# STM32F40x register map
File version: 1.5
Registers are 32-bit, read-write, reset 0x0 unless marked. A register's access mark holds for its fields unless they carry their own. Offsets are from the block's base; [hi:lo] are bit positions.

## TIM9（定时器9(通用定时器)） — 通用定时器：计数/比较/PWM/输入捕获 | General purpose timers
Base 0x40014000
Same registers: TIM12（定时器12(通用定时器)） 0x40001800
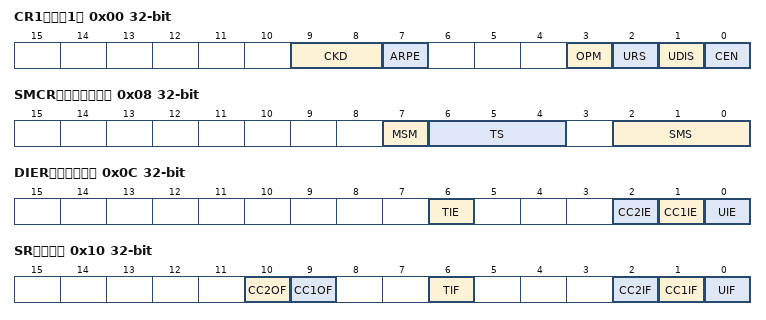
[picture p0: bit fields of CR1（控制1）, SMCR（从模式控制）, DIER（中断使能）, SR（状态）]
0x00 CR1（控制1） — 控制1：计数器使能/方向/分频 | control register 1
  [9:8] CKD — Clock division
  [7] ARPE — Auto-reload preload enable
  [3] OPM — One-pulse mode
  [2] URS — Update request source
  [1] UDIS — Update disable
  [0] CEN — Counter enable
0x04 CR2（控制2） — 控制2：主模式选择 | control register 2
  [6:4] MMS — Master mode selection
0x08 SMCR（从模式控制） — 从模式控制 | slave mode control register
  [7] MSM — Master/Slave mode
  [6:4] TS — Trigger selection
  [2:0] SMS — Slave mode selection
0x0C DIER（中断使能） — DMA/中断使能 | DMA/Interrupt enable register
  [6] TIE — Trigger interrupt enable
  [2] CC2IE — Capture/Compare 2 interrupt enable
  [1] CC1IE — Capture/Compare 1 interrupt enable
  [0] UIE — Update interrupt enable
0x10 SR（状态） — 状态：更新/捕获 标志 | status register
  [10] CC2OF — Capture/compare 2 overcapture flag
  [9] CC1OF — Capture/Compare 1 overcapture flag
  [6] TIF — Trigger interrupt flag
  [2] CC2IF — Capture/Compare 2 interrupt flag
  [1] CC1IF — Capture/compare 1 interrupt flag
  [0] UIF — Update interrupt flag
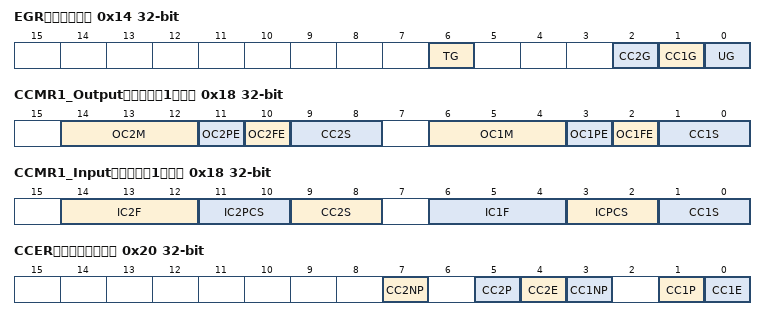
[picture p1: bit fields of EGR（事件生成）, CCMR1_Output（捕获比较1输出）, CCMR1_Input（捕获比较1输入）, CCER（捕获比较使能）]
0x14 EGR（事件生成） wo — 事件生成 | event generation register
  [6] TG — Trigger generation
  [2] CC2G — Capture/compare 2 generation
  [1] CC1G — Capture/compare 1 generation
  [0] UG — Update generation
0x18 CCMR1_Output（捕获比较1输出） — 通道1/2 输出比较模式 | capture/compare mode register 1 (output mode)
  [14:12] OC2M — Output Compare 2 mode
  [11] OC2PE — Output Compare 2 preload enable
  [10] OC2FE — Output Compare 2 fast enable
  [9:8] CC2S — Capture/Compare 2 selection
  [6:4] OC1M — Output Compare 1 mode
  [3] OC1PE — Output Compare 1 preload enable
  [2] OC1FE — Output Compare 1 fast enable
  [1:0] CC1S — Capture/Compare 1 selection
0x18 CCMR1_Input（捕获比较1输入） (alternate view of CCMR1_Output) — 通道1/2 输入捕获模式 | capture/compare mode register 1 (input mode)
  [14:12] IC2F — Input capture 2 filter
  [11:10] IC2PCS — Input capture 2 prescaler
  [9:8] CC2S — Capture/Compare 2 selection
  [6:4] IC1F — Input capture 1 filter
  [3:2] ICPCS — Input capture 1 prescaler
  [1:0] CC1S — Capture/Compare 1 selection
0x20 CCER（捕获比较使能） — 通道 使能/极性/方向 | capture/compare enable register
  [7] CC2NP — Capture/Compare 2 output Polarity
  [5] CC2P — Capture/Compare 2 output Polarity
  [4] CC2E — Capture/Compare 2 output enable
  [3] CC1NP — Capture/Compare 1 output Polarity
  [1] CC1P — Capture/Compare 1 output Polarity
  [0] CC1E — Capture/Compare 1 output enable
0x24 CNT（计数器） — 当前计数值 | counter
  [15:0] CNT — counter value
0x28 PSC（预分频） — 预分频 | prescaler
  [15:0] PSC — Prescaler value
0x2C ARR（自动重装） — 自动重装载值 | auto-reload register
  [15:0] ARR — Auto-reload value
0x34 CCR1（捕获比较1） — 通道1 比较值/捕获值 | capture/compare register 1
  [15:0] CCR1 — Capture/Compare 1 value
0x38 CCR2（捕获比较2） — 通道2 比较值/捕获值 | capture/compare register 2
  [15:0] CCR2 — Capture/Compare 2 value

## TIM10（定时器10(通用定时器)） — 通用定时器：计数/比较/PWM/输入捕获 | General-purpose-timers
Base 0x40014400
Same registers: TIM13（定时器13(通用定时器)） 0x40001C00, TIM14（定时器14(通用定时器)） 0x40002000
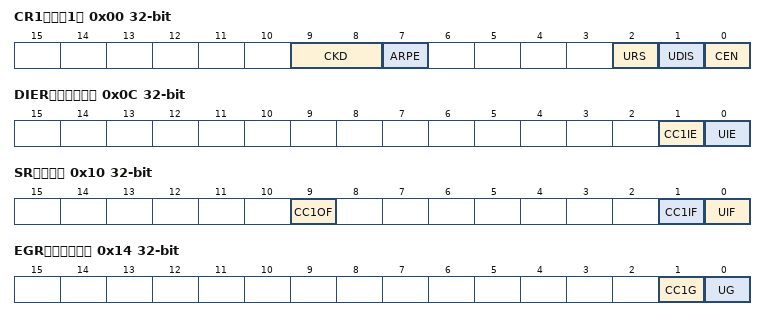
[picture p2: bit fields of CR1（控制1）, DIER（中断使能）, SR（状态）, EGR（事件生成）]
0x00 CR1（控制1） — 控制1：计数器使能/方向/分频 | control register 1
  [9:8] CKD — Clock division
  [7] ARPE — Auto-reload preload enable
  [2] URS — Update request source
  [1] UDIS — Update disable
  [0] CEN — Counter enable
0x0C DIER（中断使能） — DMA/中断使能 | DMA/Interrupt enable register
  [1] CC1IE — Capture/Compare 1 interrupt enable
  [0] UIE — Update interrupt enable
0x10 SR（状态） — 状态：更新/捕获 标志 | status register
  [9] CC1OF — Capture/Compare 1 overcapture flag
  [1] CC1IF — Capture/compare 1 interrupt flag
  [0] UIF — Update interrupt flag
0x14 EGR（事件生成） wo — 事件生成 | event generation register
  [1] CC1G — Capture/compare 1 generation
  [0] UG — Update generation
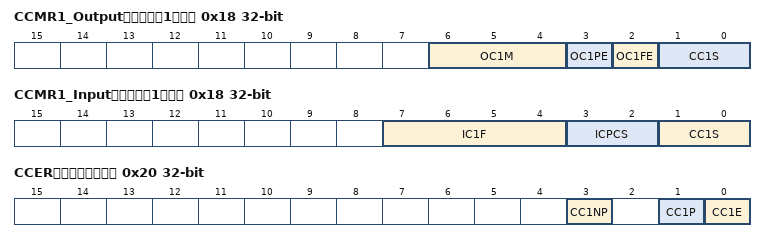
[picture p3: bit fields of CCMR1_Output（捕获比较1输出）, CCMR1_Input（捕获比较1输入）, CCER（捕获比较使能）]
0x18 CCMR1_Output（捕获比较1输出） — 通道1/2 输出比较模式 | capture/compare mode register 1 (output mode)
  [6:4] OC1M — Output Compare 1 mode
  [3] OC1PE — Output Compare 1 preload enable
  [2] OC1FE — Output Compare 1 fast enable
  [1:0] CC1S — Capture/Compare 1 selection
0x18 CCMR1_Input（捕获比较1输入） (alternate view of CCMR1_Output) — 通道1/2 输入捕获模式 | capture/compare mode register 1 (input mode)
  [7:4] IC1F — Input capture 1 filter
  [3:2] ICPCS — Input capture 1 prescaler
  [1:0] CC1S — Capture/Compare 1 selection
0x20 CCER（捕获比较使能） — 通道 使能/极性/方向 | capture/compare enable register
  [3] CC1NP — Capture/Compare 1 output Polarity
  [1] CC1P — Capture/Compare 1 output Polarity
  [0] CC1E — Capture/Compare 1 output enable
0x24 CNT（计数器） — 当前计数值 | counter
  [15:0] CNT — counter value
0x28 PSC（预分频） — 预分频 | prescaler
  [15:0] PSC — Prescaler value
0x2C ARR（自动重装） — 自动重装载值 | auto-reload register
  [15:0] ARR — Auto-reload value
0x34 CCR1（捕获比较1） — 通道1 比较值/捕获值 | capture/compare register 1
  [15:0] CCR1 — Capture/Compare 1 value

## TIM11（定时器11(通用定时器)） — 通用定时器：计数/比较/PWM/输入捕获 | General-purpose-timers
Base 0x40014800
Registers as TIM10（定时器10(通用定时器)）; these are added or differ:
0x50 OR（复用） — 定时器复用功能 | option register
  [1:0] RMP — Input 1 remapping capability
